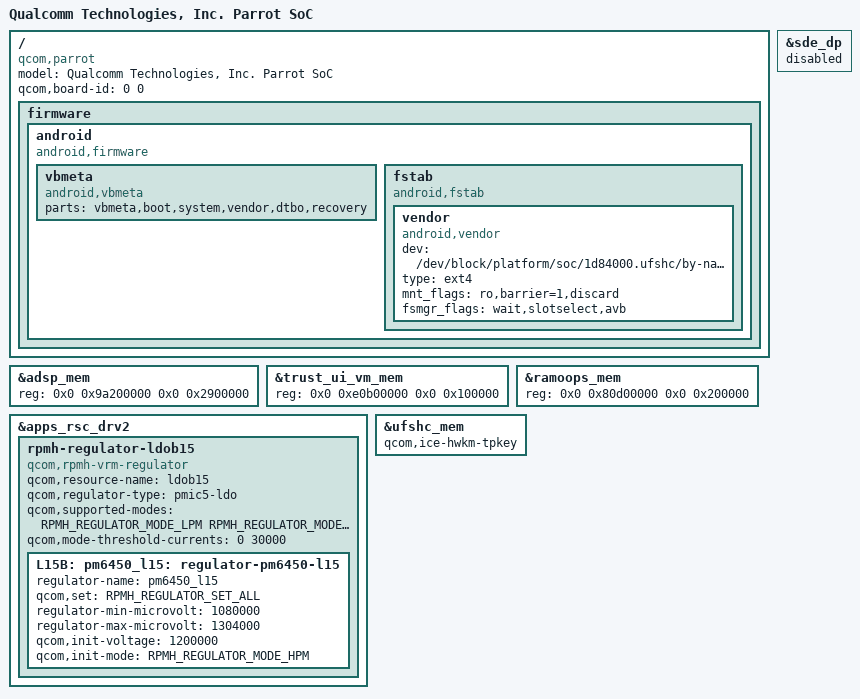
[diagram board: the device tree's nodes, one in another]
// SPDX-License-Identifier: GPL-2.0-only
/*
 * Base device tree for ruan (Redmi Pad Pro 5G / POCO Pad 5G, SM7435) on
 * Linux 6.6.
 *
 * Qualcomm's parrot.dtsi from MiCode/kernel_devicetree annibale-w-oss
 * (32fd4ddcedd4), with the reserved memory that differs on ruan's firmware
 * set back to the stock values. The bootloader then applies ruan's stock
 * dtbo overlay on top of it, as it does with the 5.10 base.
 */

/dts-v1/;

#include "parrot.dtsi"
#include <dt-bindings/regulator/qcom,rpmh-regulator-levels.h>
#include "parrot-sde.dtsi"
#include <dt-bindings/clock/qcom,aop-qmp.h>
#include <dt-bindings/clock/qcom,gpucc-parrot.h>
#include "parrot-gpu.dtsi"
#include "parrot-gpu-pwrlevels.dtsi"
#include "waipio-audio.dtsi"
#include "ruan-stubs.dtsi"

/ {
	model = "Qualcomm Technologies, Inc. Parrot SoC";
	compatible = "qcom,parrot";
	qcom,board-id = <0 0>;
};

/* ruan's ADSP firmware is larger and lives higher than on the reference board */
&adsp_mem {
	reg = <0x0 0x9a200000 0x0 0x2900000>;
};

/* The trust UI VM that ruan's hypervisor sets up */
&trust_ui_vm_mem {
	reg = <0x0 0xe0b00000 0x0 0x100000>;
};

/* Stock keeps pstore at a fixed address, keep it there */
&ramoops_mem {
	/delete-property/ alloc-ranges;
	/delete-property/ size;
	reg = <0x0 0x80d00000 0x0 0x200000>;
};

/* ruan's base has pm6450 L15, the camera sensors' digital supply */
&apps_rsc_drv2 {
	rpmh-regulator-ldob15 {
		compatible = "qcom,rpmh-vrm-regulator";
		qcom,resource-name = "ldob15";
		qcom,regulator-type = "pmic5-ldo";
		qcom,supported-modes =
			<RPMH_REGULATOR_MODE_LPM
			RPMH_REGULATOR_MODE_HPM>;
		qcom,mode-threshold-currents = <0 30000>;
		L15B:
		pm6450_l15: regulator-pm6450-l15 {
			regulator-name = "pm6450_l15";
			qcom,set = <RPMH_REGULATOR_SET_ALL>;
			regulator-min-microvolt = <1080000>;
			regulator-max-microvolt = <1304000>;
			qcom,init-voltage = <1200000>;
			qcom,init-mode = <RPMH_REGULATOR_MODE_HPM>;
		};
	};
};

/*
 * Android's first stage init reads this to know which partitions to
 * create before mounting: without the vbmeta list it never makes
 * vbmeta and boot, AVB can't verify /system and init gives up. Same as
 * the 5.10 base.
 */
/ {
	firmware {
		android {
			compatible = "android,firmware";

			vbmeta {
				compatible = "android,vbmeta";
				parts = "vbmeta,boot,system,vendor,dtbo,recovery";
			};

			fstab {
				compatible = "android,fstab";

				vendor {
					compatible = "android,vendor";
					dev = "/dev/block/platform/soc/1d84000.ufshc/by-name/vendor";
					type = "ext4";
					mnt_flags = "ro,barrier=1,discard";
					fsmgr_flags = "wait,slotselect,avb";
					status = "ok";
				};
			};
		};
	};
};

/* ruan's trustzone needs the HWKM transport key set up from HLOS */
&ufshc_mem {
	qcom,ice-hwkm-tpkey;
};

/* DisplayPort over Type-C needs the ADSP's alt mode; not brought up yet */
&sde_dp {
	status = "disabled";
};
